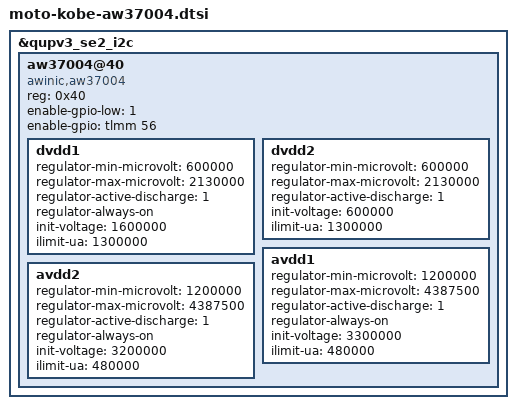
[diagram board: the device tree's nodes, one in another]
&qupv3_se2_i2c {
	status = "ok";
	aw37004@40 {
		compatible = "awinic,aw37004";
		reg = <0x40>;
		enable-gpio-low = <1>;//use init voltage
		enable-gpio = <&tlmm 56 0>;

		dvdd1 {
			regulator-min-microvolt = <600000>;
			regulator-max-microvolt = <2130000>;
			regulator-active-discharge = <1>;
			regulator-always-on;
			init-voltage = <1600000>;
			ilimit-ua = <1300000>;
		};

		dvdd2 {
			regulator-min-microvolt = <600000>;
			regulator-max-microvolt = <2130000>;
			regulator-active-discharge = <1>;
			// regulator-always-on;
			init-voltage = <600000>;
			ilimit-ua = <1300000>;
		};

		avdd1 {
			regulator-min-microvolt = <1200000>;
			regulator-max-microvolt = <4387500>;
			regulator-active-discharge = <1>;
			regulator-always-on;
			init-voltage = <3300000>;
			ilimit-ua = <480000>;
		};

		avdd2 {
			regulator-min-microvolt = <1200000>;
			regulator-max-microvolt = <4387500>;
			regulator-active-discharge = <1>;
			regulator-always-on;
			init-voltage = <3200000>;
			ilimit-ua = <480000>;
		};
	};
};
